# max32660 register map
Vendor: Maxim-Integrated; Series: ARMCM4; File version: 1.0
CPU: CM4 r2p1, little endian, MPU, FPU, 3 interrupt priority bits
Registers are 32-bit, read-write, reset 0x0 unless marked. A register's access mark holds for its fields unless they carry their own. Offsets are from the block's base; [hi:lo] are bit positions; 'fields as' and 'values as' point back to an identical list.

## SIR — System Initialization Registers.
Base 0x40000400
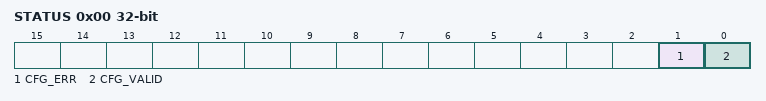
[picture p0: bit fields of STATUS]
0x00 STATUS ro — System Initialization Status Register.
  [1] CFG_ERR — Configuration Error Flag. This field is set by hardware during reset if an error in the device configuration is detected
    on read: 0=valid (config valid); 1=invalid (config invalid)
  [0] CFG_VALID — Configuration Valid Flag. This field is set to 1 by hardware during reset if the device configuration is valid.
    on read: 0=invalid (config invalid); 1=valid (config valid)
0x04 ADDR ro — Read-only field set by the SIB block if a CRC error occurs during the read of the OTP memory. Contains the failing address in OTP memory (when CRCERR equals 1).

## TMR0 — Low-Power Configurable Timer
Base 0x40010000
Same registers: TMR1 0x40011000, TMR2 0x40012000
0x00 CNT — Timer Counter Register.
  [31:0] COUNT — The current count value for the timer. This field increments as the timer counts.
0x04 CMP — Timer Compare Register.
  [31:0] COMPARE — The value in this register is used as the compare value for the timer's count value. The compare field meaning is determined by the specific mode of the timer.
0x08 PWM — Timer PWM Register.
  [31:0] PWM — Timer PWM Match: In PWM Mode, this field sets the count value for the first transition period of the PWM cycle. At the end of the cycle where CNT equals PWM, the PWM output transitions to the second period of the PWM cycle. The second PWM period count is stored in the CMP register. The value set for PWM must me less than the value set in CMP for PWM mode operation. Timer Capture Value: In Capture, Compare, and Capture/Compare modes, this field is used to store the CNT value when a Capture, Compare, or Capture/Compare event occurs.
0x0C INTR — Timer Interrupt Status Register.
  [0] IRQ — Interrupt Flag for Timer A.
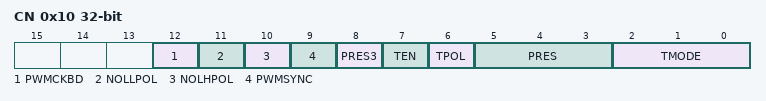
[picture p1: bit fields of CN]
0x10 CN — Timer Control Register.
  [12] PWMCKBD — PWM Phase A-Prime Output Disable
  [11] NOLLPOL — PWM Phase A-prime (Non-Overlapping Low) Polarity
  [10] NOLHPOL — PWM Phase A (Non-Overlapping High) Polarity
  [9] PWMSYNC — PWM Synchronization Mode
  [8] PRES3 — Timer Prescale Select MSB
  [7] TEN — Timer Enable
  [6] TPOL — Timer Polarity
  [5:3] PRES — Timer Prescaler Select
    0=DIV_BY_1 (Prescaler Divide-By-1); 1=DIV_BY_2 (Prescaler Divide-By-2); 2=DIV_BY_4 (Prescaler Divide-By-4); 3=DIV_BY_8 (Prescaler Divide-By-8); 4=DIV_BY_16 (Prescaler Divide-By-16); 5=DIV_BY_32 (Prescaler Divide-By-32); 6=DIV_BY_64 (Prescaler Divide-By-64); 7=DIV_BY_128 (Prescaler Divide-By-128); 0=DIV_BY_256 (Prescaler Divide-By-256); 1=DIV_BY_512 (Prescaler Divide-By-512); 2=DIV_BY_1024 (Prescaler Divide-By-1024); 3=DIV_BY_2048 (Prescaler Divide-By-2048); 4=DIV_BY_4096 (Prescaler Divide-By-4096); 5=DIV_BY_8192 (Prescaler Divide-By-8192)
  [2:0] TMODE — Mode Select
    0=ONE_SHOT (One-Shot Mode); 1=CONTINUOUS (Continuous Mode); 2=COUNTER (Counter Mode); 3=PWM (PWM Mode); 4=CAPTURE (Capture Mode); 5=COMPARE (Compare Mode); 6=GATED (Gated Mode); 7=CAPCOMP (Capture/Compare Mode)

## WDT0 — Watchdog Timer 0
Base 0x40003000
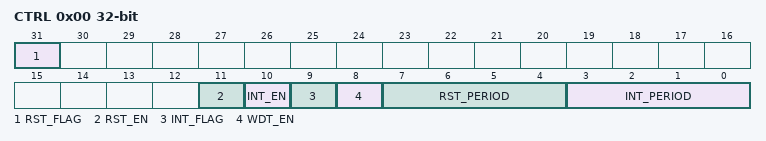
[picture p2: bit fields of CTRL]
0x00 CTRL (reset mask 0x7FFFF000) — Watchdog Timer Control Register.
  [31] RST_FLAG — Watchdog Timer Reset Flag.
    0=noEvent (The event has not occurred.); 1=occurred (The event has occurred.)
  [11] RST_EN — Watchdog Timer Reset Enable.
    0=dis (Disable.); 1=en (Enable.)
  [10] INT_EN — Watchdog Timer Interrupt Enable.
    0=dis (Disable.); 1=en (Enable.)
  [9] INT_FLAG write-1-clears — Watchdog Timer Interrupt Flag.
    0=inactive (No interrupt is pending.); 1=pending (An interrupt is pending.)
  [8] WDT_EN — Watchdog Timer Enable.
    0=dis (Disable.); 1=en (Enable.)
  [7:4] RST_PERIOD — Watchdog Reset Period. The watchdog timer will assert a reset, if enabled, if the CPU does not write the watchdog reset sequence to the WDT_RST register before the watchdog timer has counted this time period since the last timer reset.
    0=wdt2pow31 (2**31 clock cycles.); 1=wdt2pow30 (2**30 clock cycles.); 2=wdt2pow29 (2**29 clock cycles.); 3=wdt2pow28 (2**28 clock cycles.); 4=wdt2pow27 (2^27 clock cycles.); 5=wdt2pow26 (2**26 clock cycles.); 6=wdt2pow25 (2**25 clock cycles.); 7=wdt2pow24 (2**24 clock cycles.); 8=wdt2pow23 (2**23 clock cycles.); 9=wdt2pow22 (2**22 clock cycles.); 10=wdt2pow21 (2**21 clock cycles.); 11=wdt2pow20 (2**20 clock cycles.); 12=wdt2pow19 (2**19 clock cycles.); 13=wdt2pow18 (2**18 clock cycles.); 14=wdt2pow17 (2**17 clock cycles.); 15=wdt2pow16 (2**16 clock cycles.)
  [3:0] INT_PERIOD — Watchdog Interrupt Period. The watchdog timer will assert an interrupt, if enabled, if the CPU does not write the watchdog reset sequence to the WDT_RST register before the watchdog timer has counted this time period since the last timer reset.
    values as RST_PERIOD
0x04 RST wo — Watchdog Timer Reset Register.
  [7:0] WDT_RST — Writing the watchdog counter 'reset sequence' to this register resets the watchdog counter. If the watchdog count exceeds INT_PERIOD then a watchdog interrupt will occur, if enabled. If the watchdog count exceeds RST_PERIOD then a watchdog reset will occur, if enabled.
    165=seq0 (The first value to be written to reset the WDT.); 90=seq1 (The second value to be written to reset the WDT.)
